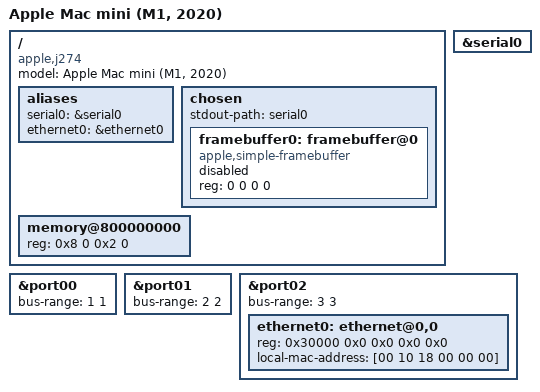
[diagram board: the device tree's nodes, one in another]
// SPDX-License-Identifier: GPL-2.0+ OR MIT
/*
 * Apple Mac mini (M1, 2020)
 *
 * target-type: J274
 *
 * Copyright The Asahi Linux Contributors
 */

/dts-v1/;

#include "t8103.dtsi"

/ {
	compatible = "apple,j274", "apple,t8103", "apple,arm-platform";
	model = "Apple Mac mini (M1, 2020)";

	aliases {
		serial0 = &serial0;
		ethernet0 = &ethernet0;
	};

	chosen {
		#address-cells = <2>;
		#size-cells = <2>;
		ranges;

		stdout-path = "serial0";

		framebuffer0: framebuffer@0 {
			compatible = "apple,simple-framebuffer", "simple-framebuffer";
			reg = <0 0 0 0>; /* To be filled by loader */
			/* Format properties will be added by loader */
			status = "disabled";
		};
	};

	memory@800000000 {
		device_type = "memory";
		reg = <0x8 0 0x2 0>; /* To be filled by loader */
	};
};

&serial0 {
	status = "okay";
};

/*
 * Force the bus number assignments so that we can declare some of the
 * on-board devices and properties that are populated by the bootloader
 * (such as MAC addresses).
 */
&port00 {
	bus-range = <1 1>;
};

&port01 {
	bus-range = <2 2>;
};

&port02 {
	bus-range = <3 3>;
	ethernet0: ethernet@0,0 {
		reg = <0x30000 0x0 0x0 0x0 0x0>;
		/* To be filled by the loader */
		local-mac-address = [00 10 18 00 00 00];
	};
};
